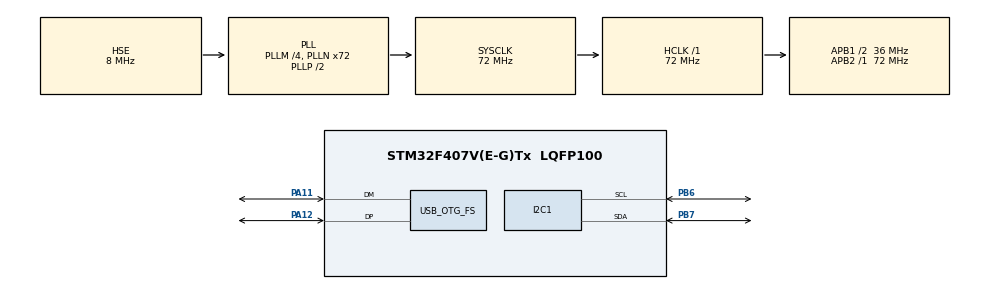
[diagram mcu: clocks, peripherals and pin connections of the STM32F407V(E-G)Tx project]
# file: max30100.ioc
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FREERTOS.BinarySemaphores01=usbSemaphore,Dynamic,NULL
FREERTOS.Mutexes01=usbMutex,Dynamic,NULL
FREERTOS.Tasks01=maxTask,0,256,StartMaxTask,Default,NULL,Dynamic,NULL,NULL;usbTask,0,256,StartUsbTask,Default,NULL,Dynamic,NULL,NULL
FREERTOS.configUSE_NEWLIB_REENTRANT=1
Mcu.Family=STM32F4
Mcu.Name=STM32F407V(E-G)Tx
Mcu.Package=LQFP100
NVIC.OTG_FS_IRQn=true\:5\:0\:false\:false\:true\:true\:false\:true\:true
NVIC.PriorityGroup=NVIC_PRIORITYGROUP_4
NVIC.TIM6_DAC_IRQn=true\:15\:0\:false\:false\:true\:false\:false\:true\:true
NVIC.TimeBase=TIM6_DAC_IRQn
NVIC.TimeBaseIP=TIM6
PA11.Mode=Device_Only
PA11.Signal=USB_OTG_FS_DM
PA12.Mode=Device_Only
PA12.Signal=USB_OTG_FS_DP
PA13.Mode=Serial_Wire
PA13.Signal=SYS_JTMS-SWDIO
PA14.Mode=Serial_Wire
PA14.Signal=SYS_JTCK-SWCLK
PB6.Mode=I2C
PB6.Signal=I2C1_SCL
PB7.Mode=I2C
PB7.Signal=I2C1_SDA
PH0-OSC_IN.Mode=HSE-External-Oscillator
PH0-OSC_IN.Signal=RCC_OSC_IN
PH1-OSC_OUT.Mode=HSE-External-Oscillator
PH1-OSC_OUT.Signal=RCC_OSC_OUT
ProjectManager.HeapSize=0x200
ProjectManager.StackSize=0x400
ProjectManager.TargetToolchain=STM32CubeIDE
RCC.48MHZClocksFreq_Value=48000000
RCC.AHBFreq_Value=72000000
RCC.APB1CLKDivider=RCC_HCLK_DIV2
RCC.APB1Freq_Value=36000000
RCC.APB1TimFreq_Value=72000000
RCC.APB2Freq_Value=72000000
RCC.APB2TimFreq_Value=72000000
RCC.CortexFreq_Value=72000000
RCC.HCLKFreq_Value=72000000
RCC.HSE_VALUE=8000000
RCC.HSI_VALUE=16000000
RCC.LSE_VALUE=32768
RCC.PLLM=4
RCC.PLLN=72
RCC.PLLQ=3
RCC.SYSCLKFreq_VALUE=72000000
RCC.SYSCLKSource=RCC_SYSCLKSOURCE_PLLCLK
RCC.VCOOutputFreq_Value=144000000
USB_DEVICE.CLASS_NAME_FS=CDC
USB_DEVICE.VirtualMode-CDC_FS=Cdc
USB_DEVICE.VirtualModeFS=Cdc_FS
USB_OTG_FS.VirtualMode=Device_Only
VP_FREERTOS_VS_CMSIS_V1.Mode=CMSIS_V1
VP_SYS_VS_tim6.Mode=TIM6
VP_USB_DEVICE_VS_USB_DEVICE_CDC_FS.Mode=CDC_FS
board=STM32F407G-DISC1

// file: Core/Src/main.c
/* USER CODE BEGIN Header */
/**
  ******************************************************************************
  * @file           : main.c
  * @brief          : Main program body
  ******************************************************************************
  * @attention
  *
  * Copyright (c) 2026 STMicroelectronics.
  * All rights reserved.
  *
  * This software is licensed under terms that can be found in the LICENSE file
  * in the root directory of this software component.
  * If no LICENSE file comes with this software, it is provided AS-IS.
  *
  ******************************************************************************
  */
/* USER CODE END Header */
#include "main.h"
#include "cmsis_os.h"
#include "usb_device.h"

/* USER CODE BEGIN Includes */
#include "max30100.h"
/* USER CODE END Includes */

I2C_HandleTypeDef hi2c1;

osThreadId maxTaskHandle;
osThreadId usbTaskHandle;
osMutexId usbMutexHandle;
osSemaphoreId usbSemaphoreHandle;
/* USER CODE BEGIN PV */
/* USER CODE BEGIN PV */

/* USER CODE END PV */

void SystemClock_Config(void);
static void MX_GPIO_Init(void);
static void MX_I2C1_Init(void);
void StartMaxTask(void const * argument);
void StartUsbTask(void const * argument);

int main(void)
{

  /* MCU Configuration--------------------------------------------------------*/

  /* Reset of all peripherals, Initializes the Flash interface and the Systick. */
  HAL_Init();

  /* Configure the system clock */
  SystemClock_Config();

  /* Initialize all configured peripherals */
  MX_GPIO_Init();
  MX_I2C1_Init();
  MX_USB_DEVICE_Init();

  /* Create the mutex(es) */
  /* definition and creation of usbMutex */
  osMutexDef(usbMutex);
  usbMutexHandle = osMutexCreate(osMutex(usbMutex));

  /* Create the semaphores(s) */
  /* definition and creation of usbSemaphore */
  osSemaphoreDef(usbSemaphore);
  usbSemaphoreHandle = osSemaphoreCreate(osSemaphore(usbSemaphore), 1);

  /* Create the thread(s) */
  /* definition and creation of maxTask */
  osThreadDef(maxTask, StartMaxTask, osPriorityNormal, 0, 256);
  maxTaskHandle = osThreadCreate(osThread(maxTask), NULL);

  /* definition and creation of usbTask */
  osThreadDef(usbTask, StartUsbTask, osPriorityNormal, 0, 256);
  usbTaskHandle = osThreadCreate(osThread(usbTask), NULL);

  /* Start scheduler */
  osKernelStart();

  /* We should never get here as control is now taken by the scheduler */
  /* Infinite loop */
  while (1)
  {

  }
}

void SystemClock_Config(void)
{
  RCC_OscInitTypeDef RCC_OscInitStruct = {0};
  RCC_ClkInitTypeDef RCC_ClkInitStruct = {0};

  /** Configure the main internal regulator output voltage
  */
  __HAL_RCC_PWR_CLK_ENABLE();
  __HAL_PWR_VOLTAGESCALING_CONFIG(PWR_REGULATOR_VOLTAGE_SCALE1);

  /** Initializes the RCC Oscillators according to the specified parameters
  * in the RCC_OscInitTypeDef structure.
  */
  RCC_OscInitStruct.OscillatorType = RCC_OSCILLATORTYPE_HSE;
  RCC_OscInitStruct.HSEState = RCC_HSE_ON;
  RCC_OscInitStruct.PLL.PLLState = RCC_PLL_ON;
  RCC_OscInitStruct.PLL.PLLSource = RCC_PLLSOURCE_HSE;
  RCC_OscInitStruct.PLL.PLLM = 4;
  RCC_OscInitStruct.PLL.PLLN = 72;
  RCC_OscInitStruct.PLL.PLLP = RCC_PLLP_DIV2;
  RCC_OscInitStruct.PLL.PLLQ = 3;
  if (HAL_RCC_OscConfig(&RCC_OscInitStruct) != HAL_OK)
  {
    Error_Handler();
  }

  /** Initializes the CPU, AHB and APB buses clocks
  */
  RCC_ClkInitStruct.ClockType = RCC_CLOCKTYPE_HCLK|RCC_CLOCKTYPE_SYSCLK
                              |RCC_CLOCKTYPE_PCLK1|RCC_CLOCKTYPE_PCLK2;
  RCC_ClkInitStruct.SYSCLKSource = RCC_SYSCLKSOURCE_PLLCLK;
  RCC_ClkInitStruct.AHBCLKDivider = RCC_SYSCLK_DIV1;
  RCC_ClkInitStruct.APB1CLKDivider = RCC_HCLK_DIV2;
  RCC_ClkInitStruct.APB2CLKDivider = RCC_HCLK_DIV1;

  if (HAL_RCC_ClockConfig(&RCC_ClkInitStruct, FLASH_LATENCY_2) != HAL_OK)
  {
    Error_Handler();
  }
}

static void MX_I2C1_Init(void)
{

  hi2c1.Instance = I2C1;
  hi2c1.Init.ClockSpeed = 100000;
  hi2c1.Init.DutyCycle = I2C_DUTYCYCLE_2;
  hi2c1.Init.OwnAddress1 = 0;
  hi2c1.Init.AddressingMode = I2C_ADDRESSINGMODE_7BIT;
  hi2c1.Init.DualAddressMode = I2C_DUALADDRESS_DISABLE;
  hi2c1.Init.OwnAddress2 = 0;
  hi2c1.Init.GeneralCallMode = I2C_GENERALCALL_DISABLE;
  hi2c1.Init.NoStretchMode = I2C_NOSTRETCH_DISABLE;
  if (HAL_I2C_Init(&hi2c1) != HAL_OK)
  {
    Error_Handler();
  }

}

static void MX_GPIO_Init(void)
{

  /* GPIO Ports Clock Enable */
  __HAL_RCC_GPIOH_CLK_ENABLE();
  __HAL_RCC_GPIOA_CLK_ENABLE();
  __HAL_RCC_GPIOB_CLK_ENABLE();

}

void HAL_TIM_PeriodElapsedCallback(TIM_HandleTypeDef *htim)
{
  if (htim->Instance == TIM6) {
    HAL_IncTick();
  }
}

void Error_Handler(void)
{
  __disable_irq();
  while (1)
  {
  }
}
